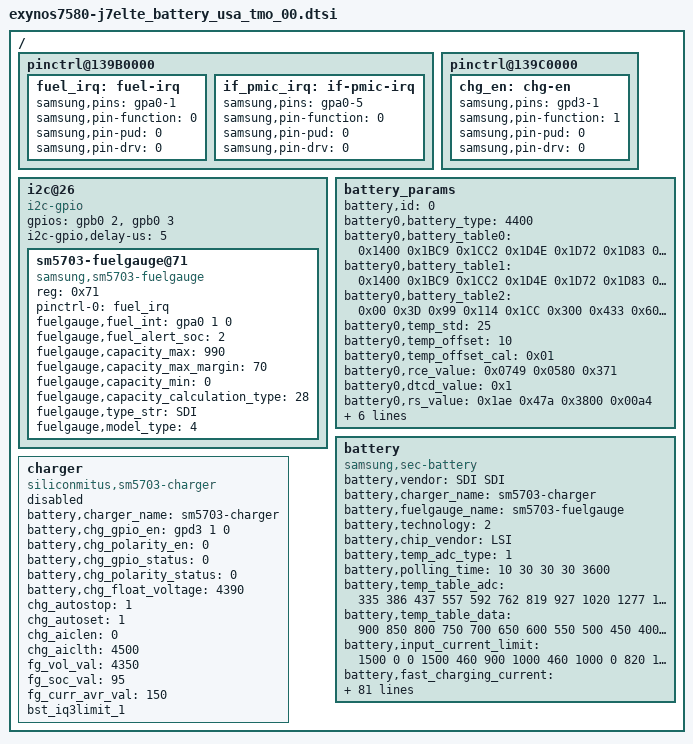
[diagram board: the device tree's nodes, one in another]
/*
 * SAMSUNG UNIVERSAL7580 board device tree source
 *
 * Copyright (c) 2015 Samsung Electronics Co., Ltd.
 *		http://www.samsung.com
 *
 * This program is free software; you can redistribute it and/or modify
 * it under the terms of the GNU General Public License version 2 as
 * published by the Free Software Foundation.
*/

/ {
	pinctrl@139B0000 {
		fuel_irq: fuel-irq {
			samsung,pins = "gpa0-1";
			samsung,pin-function = <0>;
			samsung,pin-pud = <0>;
			samsung,pin-drv = <0>;
		};
	};

	pinctrl@139B0000 {
		if_pmic_irq: if-pmic-irq {
			samsung,pins = "gpa0-5";
			samsung,pin-function = <0>;
			samsung,pin-pud = <0>;
			samsung,pin-drv = <0>;
		};
	};

	pinctrl@139C0000 {
		chg_en: chg-en {
			samsung,pins = "gpd3-1";
			samsung,pin-function = <1>;
			samsung,pin-pud = <0>;
			samsung,pin-drv = <0>;
		};
	};

	i2c@26 {
		compatible = "i2c-gpio";
		gpios = <&gpb0 2 0
			&gpb0 3 0>;
		i2c-gpio,delay-us = <5>;
		#address-cells = <1>;
		#size-cells = <0>;
		status = "okay";
		sm5703-fuelgauge@71 {
			compatible = "samsung,sm5703-fuelgauge";
			reg = <0x71>;
			pinctrl-names = "default";
			pinctrl-0 = <&fuel_irq>;
			fuelgauge,fuel_int = <&gpa0 1 0>;
			fuelgauge,fuel_alert_soc = <2>;
			fuelgauge,capacity_max = <990>;
			fuelgauge,capacity_max_margin = <70>;
			fuelgauge,capacity_min = <0>;
			fuelgauge,capacity_calculation_type = <28>;
			fuelgauge,type_str = "SDI";
			fuelgauge,model_type = <4>;
		};
	};

	battery_params {
		battery,id = <0>;
		battery0,battery_type = <4400>; /* 4200 4350 4400 */
		battery0,battery_table0 = <0x1400 0x1BC9 0x1CC2 0x1D4E 0x1D72 0x1D83 0x1DD6 0x1E1E 0x1E55 0x1E99 0x1F05 0x1F81 0x2029 0x20F0 0x22C5 0x2400>;
		battery0,battery_table1 = <0x1400 0x1BC9 0x1CC2 0x1D4E 0x1D72 0x1D83 0x1DD6 0x1E1E 0x1E55 0x1E99 0x1F05 0x1F81 0x2029 0x20F0 0x22C5 0x2400>;
		battery0,battery_table2 = <0x00 0x3D 0x99 0x114 0x1CC 0x300 0x433 0x600 0x866 0xACC 0xD33 0xE66 0x10CC 0x1333 0x1800 0x1812>;
		battery0,temp_std = <25>;
		battery0,temp_offset = <10>;
		battery0,temp_offset_cal = <0x01>;
		battery0,rce_value = <0x0749 0x0580 0x371>;
		battery0,dtcd_value = <0x1>;
		battery0,rs_value = <0x1ae 0x47a 0x3800 0x00a4>; /*rs mix_factor max min*/
		battery0,vit_period = <0x350a>;
		battery0,mix_value = <0x0503 0x0004>; /*mix_rate init_blank*/
		battery0,topoff_soc = <0x0 0x05>; /*enable soc*/
		battery0,volt_cal = <0x809e>;
		battery0,curr_cal = <0x7485>;
		battery0,charge_offset_cal = <0x02>;
	};

	battery {
		status = "okay";

		pinctrl-names = "default";

		compatible = "samsung,sec-battery";
		battery,vendor = "SDI SDI";
		battery,charger_name = "sm5703-charger";
		battery,fuelgauge_name = "sm5703-fuelgauge";
		battery,technology = <2>; /* POWER_SUPPLY_TECHNOLOGY_LION */
		/* .temp_cohot = -1000; */
		/* .temp_cocold = -4325; */

		battery,chip_vendor = "LSI";
		battery,temp_adc_type = <1>; /* SEC_BATTERY_ADC_TYPE_AP */

		battery,polling_time = <10 30 30 30 3600>;

		battery,temp_table_adc = <335 386 437 557 592 762 819 927 1020 1277 1517 1639 1826 2094 2359 2500 2717 2915
						3095 3276 3423 3481 3539>;

		battery,temp_table_data = <900 850 800 750 700 650 600 550 500 450 400 350 300 250 200 150 100 50
						0 (-50) (-100) (-150) (-200)>;

		battery,input_current_limit = <1500 0 0 1500 460 900 1000 460 1000 0 820 1450 1500 0 0 400 700 1300 300 1000 1500 0 1450 1000 1500 80 1500 1500 1400 1000 1000>;
		battery,fast_charging_current = <2000 0 0 2000 460 1200 1000 460 1200 0 1200 1600 2000 0 0 400 700 1300 300 1000 1900 0 2000 1000 2000 80 1800 1000 1400 0 1000>;
		battery,full_check_current_1st = <200 0 0 200 200 200 200 200 200 0 200 200 200 0 0 200 200 200 200 200 200 0 200 200 200 0 200 200 200 200>;
		battery,full_check_current_2nd = <150 0 0 150 150 150 150 150 150 0 150 150 150 0 0 150 150 150 150 150 150 0 150 150 150 0 150 150 150 0 150>;

		battery,inbat_voltage = <0>;
		battery,inbat_voltage_table_adc = <3120 3101 3061 3038 3001 2956 2920 2887 2856 2814
						2793 2754 2720 2677 2641 2613 2572 2531 2502 2467 2436>;
		battery,inbat_voltage_table_data = <438 435 430 425 420 415 410 405 400 395
						390 385 380 375 370 365 360 355 350 345 340>;

		battery,adc_check_count = <5>;

		battery,cable_check_type = <4>; /* SEC_BATTERY_CABLE_CHECK_PSY */
		battery,cable_source_type = <1>; /* SEC_BATTERY_CABLE_SOURCE_EXTERNAL */
		battery,event_waiting_time = <600>;
		battery,polling_type = <1>; /* SEC_BATTERY_MONITOR_ALARM */
		battery,monitor_initial_count = <0>;

		battery,battery_check_type = <6>; /* SEC_BATTERY_CHECK_INT */
		battery,check_count = <0>;

		battery,bat_irq_gpio = <&gpa0 0 0>;
		battery,bat_irq_attr = <0x00002003>; /*  IRQF_TRIGGER_RISING	0x00000001
							 IRQF_TRIGGER_FALLING	0x00000002
							 IRQF_ONESHOT		0x00002000
							*/
		battery,check_adc_max = <1440>;
		battery,check_adc_min = <0>;

		battery,ovp_uvlo_check_type = <3>; /* SEC_BATTERY_OVP_UVLO_CHGPOLLING */

		battery,thermal_source = <2>; /* SEC_BATTERY_THERMAL_SOURCE_ADC */

		battery,temp_check_type = <2>; /* SEC_BATTERY_TEMP_CHECK_TEMP */
		battery,temp_check_count = <1>;
		battery,temp_highlimit_threshold_event = <800>;
		battery,temp_highlimit_recovery_event = <750>;
		battery,temp_high_threshold_event = <550>;
		battery,temp_high_recovery_event = <500>;
		battery,temp_low_threshold_event = <(-50)>;
		battery,temp_low_recovery_event = <0>;
		battery,temp_highlimit_threshold_normal = <800>;
		battery,temp_highlimit_recovery_normal = <750>;
		battery,temp_high_threshold_normal = <550>;
		battery,temp_high_recovery_normal = <500>;
		battery,temp_low_threshold_normal = <(-50)>;
		battery,temp_low_recovery_normal = <0>;
		battery,temp_highlimit_threshold_lpm = <800>;
		battery,temp_highlimit_recovery_lpm = <750>;
		battery,temp_high_threshold_lpm = <550>;
		battery,temp_high_recovery_lpm = <500>;
		battery,temp_low_threshold_lpm = <(-50)>;
		battery,temp_low_recovery_lpm = <0>;
		battery,full_check_type = <2>; /* SEC_BATTERY_FULLCHARGED_FG_CURRENT */
		battery,full_check_type_2nd = <2>; /* SEC_BATTERY_FULLCHARGED_FG_CURRENT */
		battery,full_check_count = <1>;
		battery,chg_gpio_full_check = <0>;
		battery,chg_polarity_full_check = <1>;

		/* SEC_BATTERY_FULL_CONDITION_SOC |
		   SEC_BATTERY_FULL_CONDITION_NOTIMEFULL |
		   SEC_BATTERY_FULL_CONDITION_VCELL */
		battery,full_condition_type = <13>;
		battery,full_condition_soc = <93>;
		battery,full_condition_vcell = <4290>;

		battery,recharge_check_count = <2>;
		battery,recharge_condition_type = <4>; /* SEC_BATTERY_RECHARGE_CONDITION_VCELL */
		battery,recharge_condition_soc = <98>;
		battery,recharge_condition_vcell = <4340>;

		battery,charging_total_time = <21600>;
		battery,recharging_total_time = <5400>;
		battery,charging_reset_time = <0>;

		battery,always_enable;

		io-channels = <&exynos_adc 1>, <&exynos_adc 3>;
		io-channel-names = "adc-temp", "bat-id";
		#io-channel-cells = <1>;
		io-channel-ranges;

		battery,chg_float_voltage = <4390>;

		battery,self_discharging_en;
		battery,force_discharging_limit = <650>;
		battery,force_discharging_recov = <550>;
		battery,self_discharging_voltage_limit = <4250>;
		battery,discharging_adc_max = <2600>;
		battery,discharging_adc_min = <1700>;
		battery,discharging_ntc_limit = <2750>;

		battery,swelling_high_temp_block = <500>;
		battery,swelling_high_temp_recov = <450>;
		battery,swelling_low_temp_block = <50>;
		battery,swelling_low_temp_recov = <100>;
		battery,swelling_low_chg_current = <1500>; /* 0.5C */
		battery,swelling_high_chg_current = <2000>; /* 1C */
		battery,swelling_full_check_current_2nd = <150>; /* 0.05C */
		battery,swelling_drop_float_voltage = <4200>;
		battery,swelling_high_rechg_voltage = <4150>;
		battery,swelling_low_rechg_voltage = <4050>;
		battery,swelling_block_time = <600>;
	};

	charger {
		status = "disable";
		compatible = "siliconmitus,sm5703-charger";

		/* Charger */
		battery,charger_name = "sm5703-charger";
		battery,chg_gpio_en = <&gpd3 1 0>;
		battery,chg_polarity_en = <0>;
		battery,chg_gpio_status = <0>;
		battery,chg_polarity_status = <0>;
		battery,chg_float_voltage = <4390>;
		chg_autostop = <1>;
		chg_autoset = <1>;
		chg_aiclen = <0>;
		chg_aiclth = <4500>;
		fg_vol_val = <4350>;
		fg_soc_val = <95>;
		fg_curr_avr_val = <150>;
		bst_iq3limit_1;
	};
};
